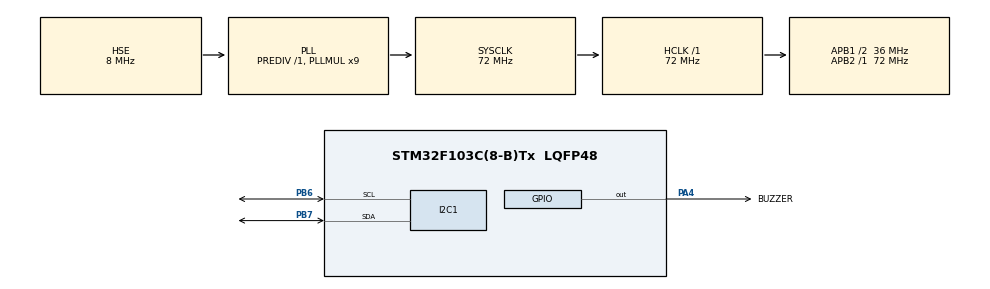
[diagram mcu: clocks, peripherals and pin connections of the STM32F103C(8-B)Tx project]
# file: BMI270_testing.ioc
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I2C1.I2C_Mode=I2C_Standard
Mcu.Family=STM32F1
Mcu.Name=STM32F103C(8-B)Tx
Mcu.Package=LQFP48
NVIC.PriorityGroup=NVIC_PRIORITYGROUP_4
PA13.Mode=Serial_Wire
PA13.Signal=SYS_JTMS-SWDIO
PA14.Mode=Serial_Wire
PA14.Signal=SYS_JTCK-SWCLK
PA4.GPIO_Label=BUZZER
PA4.Signal=GPIO_Output
PB6.Mode=I2C
PB6.Signal=I2C1_SCL
PB7.Mode=I2C
PB7.Signal=I2C1_SDA
PC14-OSC32_IN.Mode=LSE-External-Oscillator
PC14-OSC32_IN.Signal=RCC_OSC32_IN
PC15-OSC32_OUT.Mode=LSE-External-Oscillator
PC15-OSC32_OUT.Signal=RCC_OSC32_OUT
PD0-OSC_IN.Mode=HSE-External-Oscillator
PD0-OSC_IN.Signal=RCC_OSC_IN
PD1-OSC_OUT.Mode=HSE-External-Oscillator
PD1-OSC_OUT.Signal=RCC_OSC_OUT
ProjectManager.HeapSize=0x200
ProjectManager.StackSize=0x400
ProjectManager.TargetToolchain=STM32CubeIDE
RCC.AHBFreq_Value=72000000
RCC.APB1CLKDivider=RCC_HCLK_DIV2
RCC.APB1Freq_Value=36000000
RCC.APB1TimFreq_Value=72000000
RCC.APB2Freq_Value=72000000
RCC.APB2TimFreq_Value=72000000
RCC.HCLKFreq_Value=72000000
RCC.PLLMUL=RCC_PLL_MUL9
RCC.PLLSourceVirtual=RCC_PLLSOURCE_HSE
RCC.SYSCLKFreq_VALUE=72000000
RCC.SYSCLKSource=RCC_SYSCLKSOURCE_PLLCLK
RCC.USBFreq_Value=72000000
board=custom

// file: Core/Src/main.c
/* USER CODE BEGIN Header */
/**
  ******************************************************************************
  * @file           : main.c
  * @brief          : Main program body
  ******************************************************************************
  * @attention
  *
  * Copyright (c) 2026 STMicroelectronics.
  * All rights reserved.
  *
  * This software is licensed under terms that can be found in the LICENSE file
  * in the root directory of this software component.
  * If no LICENSE file comes with this software, it is provided AS-IS.
  *
  ******************************************************************************
  */
/* USER CODE END Header */
#include "main.h"

/* USER CODE BEGIN Includes */
#include "stdio.h"
#include "bmi2.h"
#include "bmi270.h"
#include "bmi2_defs.h"
/* USER CODE END Includes */

I2C_HandleTypeDef hi2c1;

void SystemClock_Config(void);
static void MX_GPIO_Init(void);
static void MX_I2C1_Init(void);

int main(void)
{

  /* MCU Configuration--------------------------------------------------------*/

  /* Reset of all peripherals, Initializes the Flash interface and the Systick. */
  HAL_Init();

  /* Configure the system clock */
  SystemClock_Config();

  /* Initialize all configured peripherals */
  MX_GPIO_Init();
  MX_I2C1_Init();
  /* USER CODE BEGIN 2 */
  struct bmi2_dev dev;
  struct bmi2_sens_data sensor_data;
  dev.intf_ptr = &hi2c1;   // MUST
  dev.intf = BMI2_I2C_INTF;
  dev.read = bmi2_i2c_read;
  dev.write = bmi2_i2c_write;
  dev.delay_us = bmi2_delay_us;
  dev.read_write_len = 8;

  int8_t rslt;
  uint8_t test = 0xB6;  // soft reset command

  if (HAL_I2C_Mem_Write(&hi2c1, (0x69 << 1), 0x7E, I2C_MEMADD_SIZE_8BIT, &test, 1, 100) == HAL_OK)
  {
      printf("Soft reset write OK\n");
  }
  else
  {
      printf("Soft reset write FAIL\n");
  }
  /* INIT */
  rslt = bmi270_init(&dev);
  printf("Init: %d\n", rslt);

  HAL_Delay(200);

  /* STATUS CHECK */
  uint8_t status = 0;
  bmi2_get_regs(0x21, &status, 1, &dev);
  printf("Status: 0x%X\n", status);

  /* ENABLE */
  uint8_t sens_list[2] = { BMI2_ACCEL, BMI2_GYRO };
  rslt = bmi270_sensor_enable(sens_list, 2, &dev);
  printf("Enable: %d\n", rslt);

  HAL_Delay(100);

  /* CONFIG */
  struct bmi2_sens_config config[2];

  config[0].type = BMI2_ACCEL;
  config[1].type = BMI2_GYRO;

  bmi270_get_sensor_config(config, 2, &dev);

  config[0].cfg.acc.odr = BMI2_ACC_ODR_100HZ;
  config[0].cfg.acc.range = BMI2_ACC_RANGE_2G;
  config[0].cfg.acc.bwp = BMI2_ACC_NORMAL_AVG4;

  config[1].cfg.gyr.odr = BMI2_GYR_ODR_100HZ;
  config[1].cfg.gyr.range = BMI2_GYR_RANGE_2000;
  config[1].cfg.gyr.bwp = BMI2_GYR_NORMAL_MODE;

  rslt = bmi270_set_sensor_config(config, 2, &dev);
  printf("Config: %d\n", rslt);

  HAL_Delay(100);
  /* USER CODE END 2 */

  /* Infinite loop */
  /* USER CODE BEGIN WHILE */
  while (1)
  {

	  bmi2_get_sensor_data(&sensor_data, &dev);

	     printf("AX:%d AY:%d AZ:%d | GX:%d GY:%d GZ:%d\r\n",
	            sensor_data.acc.x,
	            sensor_data.acc.y,
	            sensor_data.acc.z,
	            sensor_data.gyr.x,
	            sensor_data.gyr.y,
	            sensor_data.gyr.z);

	     HAL_Delay(100);

    /* USER CODE END WHILE */

  }
}

void SystemClock_Config(void)
{
  RCC_OscInitTypeDef RCC_OscInitStruct = {0};
  RCC_ClkInitTypeDef RCC_ClkInitStruct = {0};

  /** Initializes the RCC Oscillators according to the specified parameters
  * in the RCC_OscInitTypeDef structure.
  */
  RCC_OscInitStruct.OscillatorType = RCC_OSCILLATORTYPE_HSE;
  RCC_OscInitStruct.HSEState = RCC_HSE_ON;
  RCC_OscInitStruct.HSEPredivValue = RCC_HSE_PREDIV_DIV1;
  RCC_OscInitStruct.HSIState = RCC_HSI_ON;
  RCC_OscInitStruct.PLL.PLLState = RCC_PLL_ON;
  RCC_OscInitStruct.PLL.PLLSource = RCC_PLLSOURCE_HSE;
  RCC_OscInitStruct.PLL.PLLMUL = RCC_PLL_MUL9;
  if (HAL_RCC_OscConfig(&RCC_OscInitStruct) != HAL_OK)
  {
    Error_Handler();
  }

  /** Initializes the CPU, AHB and APB buses clocks
  */
  RCC_ClkInitStruct.ClockType = RCC_CLOCKTYPE_HCLK|RCC_CLOCKTYPE_SYSCLK
                              |RCC_CLOCKTYPE_PCLK1|RCC_CLOCKTYPE_PCLK2;
  RCC_ClkInitStruct.SYSCLKSource = RCC_SYSCLKSOURCE_PLLCLK;
  RCC_ClkInitStruct.AHBCLKDivider = RCC_SYSCLK_DIV1;
  RCC_ClkInitStruct.APB1CLKDivider = RCC_HCLK_DIV2;
  RCC_ClkInitStruct.APB2CLKDivider = RCC_HCLK_DIV1;

  if (HAL_RCC_ClockConfig(&RCC_ClkInitStruct, FLASH_LATENCY_2) != HAL_OK)
  {
    Error_Handler();
  }
}

static void MX_I2C1_Init(void)
{

  hi2c1.Instance = I2C1;
  hi2c1.Init.ClockSpeed = 100000;
  hi2c1.Init.DutyCycle = I2C_DUTYCYCLE_2;
  hi2c1.Init.OwnAddress1 = 0;
  hi2c1.Init.AddressingMode = I2C_ADDRESSINGMODE_7BIT;
  hi2c1.Init.DualAddressMode = I2C_DUALADDRESS_DISABLE;
  hi2c1.Init.OwnAddress2 = 0;
  hi2c1.Init.GeneralCallMode = I2C_GENERALCALL_DISABLE;
  hi2c1.Init.NoStretchMode = I2C_NOSTRETCH_DISABLE;
  if (HAL_I2C_Init(&hi2c1) != HAL_OK)
  {
    Error_Handler();
  }

}

static void MX_GPIO_Init(void)
{
  GPIO_InitTypeDef GPIO_InitStruct = {0};

  /* GPIO Ports Clock Enable */
  __HAL_RCC_GPIOC_CLK_ENABLE();
  __HAL_RCC_GPIOD_CLK_ENABLE();
  __HAL_RCC_GPIOA_CLK_ENABLE();
  __HAL_RCC_GPIOB_CLK_ENABLE();

  /*Configure GPIO pin Output Level */
  HAL_GPIO_WritePin(BUZZER_GPIO_Port, BUZZER_Pin, GPIO_PIN_RESET);

  /*Configure GPIO pin : BUZZER_Pin */
  GPIO_InitStruct.Pin = BUZZER_Pin;
  GPIO_InitStruct.Mode = GPIO_MODE_OUTPUT_PP;
  GPIO_InitStruct.Pull = GPIO_NOPULL;
  GPIO_InitStruct.Speed = GPIO_SPEED_FREQ_LOW;
  HAL_GPIO_Init(BUZZER_GPIO_Port, &GPIO_InitStruct);

}

void Error_Handler(void)
{
  __disable_irq();
  while (1)
  {
  }
}
